BO_ 166 LKAS_COMMAND: 8 XXX
 SG_ LKAS_STEERING_TORQUE : 10|11@0+ (1,-1024) [0|1] "" XXX
 SG_ LKAS_CONTROL_BIT : 24|3@1+ (1,0) [0|1] "" XXX
 SG_ DASM_FAULT : 51|1@0+ (1,0) [0|1] "" XXX
 SG_ COUNTER : 55|4@0+ (1,0) [0|15] "" XXX
 SG_ CHECKSUM : 63|8@0+ (1,0) [0|255] "" XXX

BO_ 258 STEERING: 8 XXX
 SG_ STEER_ANGLE : 5|14@0+ (0.5,-2048) [-2048|2047] "deg" XXX
 SG_ STEERING_RATE : 21|14@0+ (0.5,-2048) [-2048|2047] "deg/s" XXX
 SG_ UNKNOWN_STEERING : 50|3@0+ (1,0) [0|15] "" XXX
 SG_ COUNTER : 55|4@0+ (1,0) [0|15] "" XXX
 SG_ CHECKSUM : 63|8@0+ (1,0) [0|255] "" XXX

BO_ 284 ESP_8: 8 XXX
 SG_ BRK_PRESSURE : 3|12@0+ (1,0) [0|1] "" XXX
 SG_ BRAKE_PEDAL : 19|12@0+ (1,0) [0|1] "" XXX
 SG_ Vehicle_Speed : 39|16@0+ (0.0078125,0) [0|511.984375] "km/h" XXX
 SG_ COUNTER : 55|4@0+ (1,0) [0|15] "" XXX
 SG_ CHECKSUM : 63|8@0+ (1,0) [0|255] "" XXX

BO_ 320 ESP_1: 8 XXX
 SG_ Brake_Pedal_State : 2|2@1+ (1,0) [0|0] "" XXX
 SG_ Vehicle_Speed : 33|10@0+ (0.5,0) [0|511] "km/h" XXX
 SG_ COUNTER : 55|4@0+ (1,0) [0|15] "" XXX
 SG_ CHECKSUM : 63|8@0+ (1,0) [0|255] "" XXX
 SG_ BRAKE_PRESSED_ACC : 6|1@0+ (1,0) [0|3] "" XXX

BO_ 344 ESP_6: 8 XXX
 SG_ WHEEL_SPEED_FL : 5|14@0+ (0.5,0) [0|8191] "rpm" XXX
 SG_ WHEEL_SPEED_FR : 21|14@0+ (0.5,0) [0|8191] "rpm" XXX
 SG_ WHEEL_SPEED_RL : 37|14@0+ (0.5,0) [0|8191] "rpm" XXX
 SG_ WHEEL_SPEED_RR : 53|14@0+ (0.5,0) [0|8191] "rpm" XXX

BO_ 464 ORC_1: 8 XXX
 SG_ SEATBELT_DRIVER_UNLATCHED : 13|1@0+ (1,0) [0|1] "" XXX

BO_ 500 DAS_3: 8 XXX
 SG_ ENGINE_TORQUE_REQUEST : 4|13@0+ (0.25,-500) [-500|1547.5] "Nm" XXX
 SG_ ENGINE_TORQUE_REQUEST_MAX : 7|1@0+ (1,0) [0|1] "" XXX
 SG_ ACC_STANDSTILL : 5|1@0+ (1,0) [0|1] ""  XXX
 SG_ ACC_AVAILABLE : 20|1@0+ (1,0) [0|1] "" XXX
 SG_ ACC_ACTIVE : 21|1@0+ (1,0) [0|1] "" XXX
 SG_ ACC_FAULTED : 47|1@0+ (1,0) [0|1] "" XXX
 SG_ BRAKE_MAYBE : 18|11@0+ (1,0) [0|255] "" XXX
 SG_ BRAKE_BOOL_1 : 36|1@0+ (1,0) [0|3] "" XXX
 SG_ COUNTER : 55|4@0+ (1,0) [0|15] "" XXX
 SG_ CHECKSUM : 63|8@0+ (1,0) [0|255] "" XXX

BO_ 544 EPS_2: 8 XXX
 SG_ LKAS_STATE : 23|4@0+ (1,0) [0|15] "" XXX
 SG_ COLUMN_TORQUE : 2|11@0+ (1,-1024) [-1024|1023] "" XXX
 SG_ TORQUE_OVERLAY_STATUS : 6|4@0+ (1,0) [0|15] "" XXX
 SG_ EPS_TORQUE_MOTOR_RAW : 19|12@0+ (1,-2048) [-2048|2047] "" XXX
 SG_ EPS_TORQUE_MOTOR : 34|11@0+ (1,-1024) [-1024|1023] "" XXX
 SG_ AUTO_PARK_HAS_CONTROL_2 : 51|1@0+ (1,0) [0|1] "" XXX
 SG_ COUNTER : 55|4@0+ (1,0) [0|15] "" XXX
 SG_ CHECKSUM : 63|8@0+ (1,0) [0|255] "" XXX

BO_ 559 ECM_5: 8 XXX
 SG_ Accelerator_Position : 0|8@1+ (0.4,0) [0|100] "%" XXX
 SG_ COUNTER : 55|4@0+ (1,0) [0|15] "" XXX
 SG_ CHECKSUM : 63|8@0+ (1,0) [0|255] "" XXX

BO_ 571 CRUISE_BUTTONS: 3 XXX
 SG_ ACC_Cancel : 0|1@1+ (1,0) [0|0] "" XXX
 SG_ ACC_Distance_Dec : 1|1@1+ (1,0) [0|0] "" XXX
 SG_ ACC_Accel : 2|1@1+ (1,0) [0|0] "" XXX
 SG_ ACC_Decel : 3|1@1+ (1,0) [0|0] "" XXX
 SG_ ACC_Resume : 4|1@0+ (1,0) [0|1] "" XXX
 SG_ Cruise_OnOff : 6|1@1+ (1,0) [0|0] "" XXX
 SG_ ACC_OnOff : 7|1@1+ (1,0) [0|0] "" XXX
 SG_ ACC_Distance_Inc : 8|1@1+ (1,0) [0|0] "" XXX
 SG_ COUNTER : 15|4@0+ (1,0) [0|15] "" XXX
 SG_ CHECKSUM : 23|8@0+ (1,0) [0|255] "" XXX

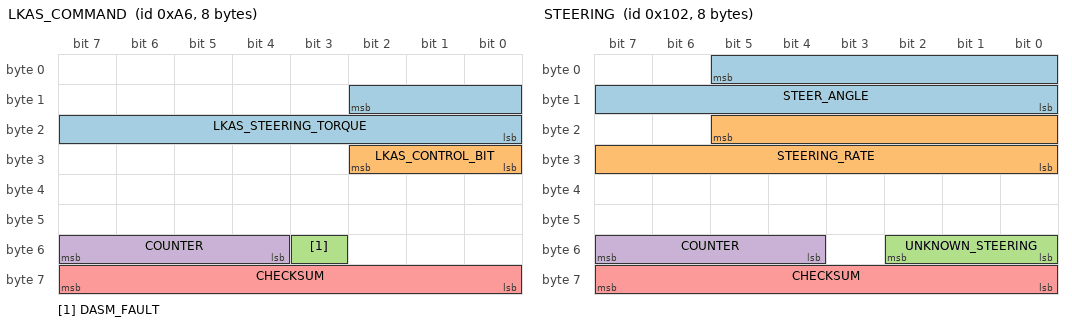
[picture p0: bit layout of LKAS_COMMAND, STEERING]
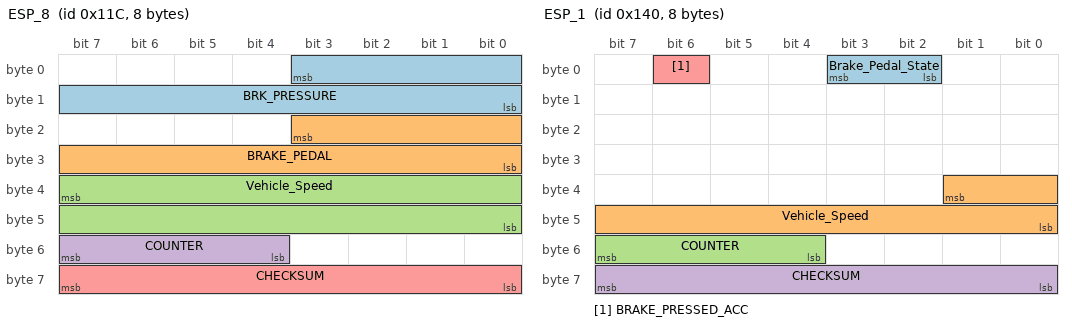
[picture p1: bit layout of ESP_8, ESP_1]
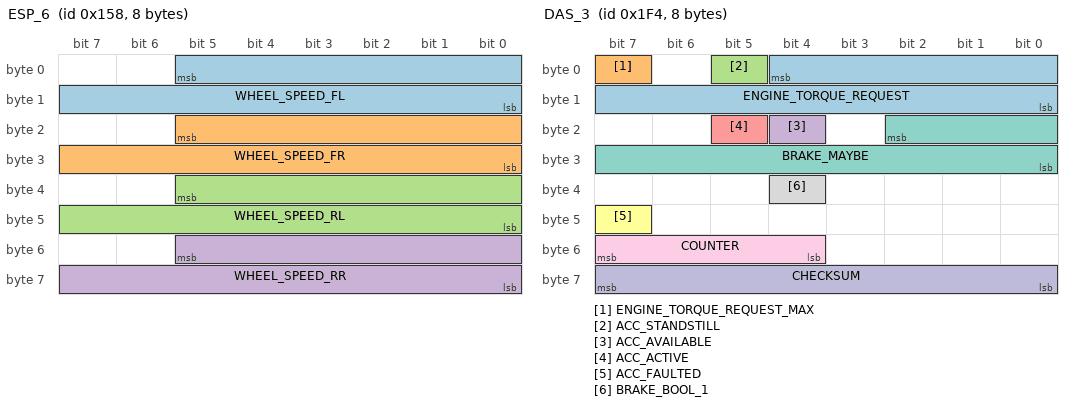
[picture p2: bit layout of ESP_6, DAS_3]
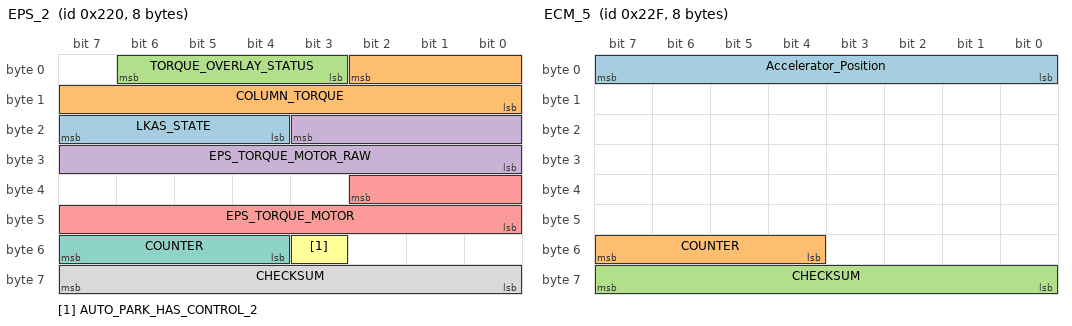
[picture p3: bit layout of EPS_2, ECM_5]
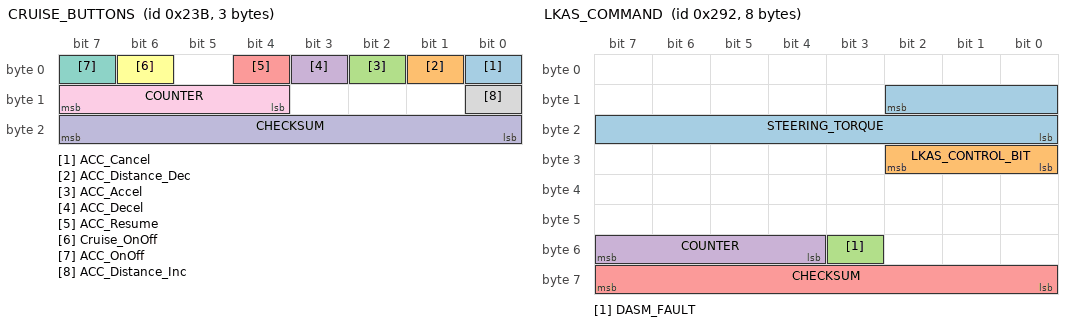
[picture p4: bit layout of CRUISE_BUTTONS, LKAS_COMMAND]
BO_ 658 LKAS_COMMAND: 8 XXX
 SG_ STEERING_TORQUE : 10|11@0+ (1,-1024) [0|1] "" XXX
 SG_ LKAS_CONTROL_BIT : 24|3@1+ (1,0) [0|1] "" XXX
 SG_ DASM_FAULT : 51|1@0+ (1,0) [0|1] "" XXX
 SG_ COUNTER : 55|4@0+ (1,0) [0|15] "" XXX
 SG_ CHECKSUM : 63|8@0+ (1,0) [0|255] "" XXX

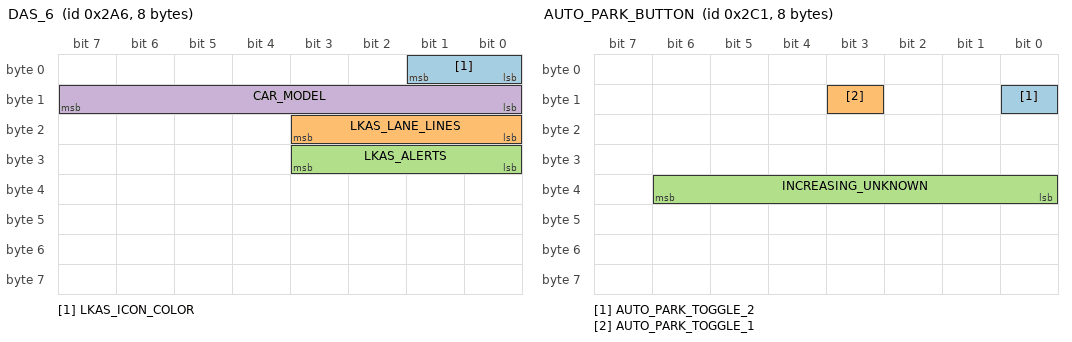
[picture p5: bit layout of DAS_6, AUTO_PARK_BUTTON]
BO_ 678 DAS_6: 8 XXX
 SG_ LKAS_ICON_COLOR : 1|2@0+ (1,0) [0|3] "" XXX
 SG_ LKAS_LANE_LINES : 19|4@0+ (1,0) [0|1] "" XXX
 SG_ LKAS_ALERTS : 27|4@0+ (1,0) [0|1] "" XXX
 SG_ CAR_MODEL : 15|8@0+ (1,0) [0|255] "" XXX

BO_ 705 AUTO_PARK_BUTTON: 8 XXX
 SG_ AUTO_PARK_TOGGLE_2 : 8|1@0+ (1,0) [0|1] "" XXX
 SG_ AUTO_PARK_TOGGLE_1 : 11|1@0+ (1,0) [0|1] "" XXX
 SG_ INCREASING_UNKNOWN : 38|7@0+ (1,0) [0|15] "" XXX

BO_ 720 BSM_1: 6 XXX
 SG_ RIGHT_STATUS : 0|3@1+ (1,0) [0|0] "" XXX
 SG_ LEFT_STATUS : 3|3@1+ (1,0) [0|0] "" XXX

BO_ 792 STEERING_LEVERS: 8 XXX
 SG_ TURN_SIGNALS : 0|2@1+ (1,0) [0|3] "" XXX
 SG_ HIGH_BEAM_PUSHED_IN : 2|1@0+ (1,0) [0|3] "" XXX

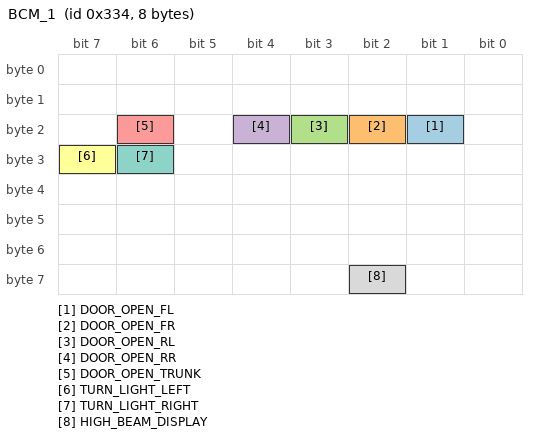
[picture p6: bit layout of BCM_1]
BO_ 820 BCM_1: 8 XXX
 SG_ DOOR_OPEN_FL : 17|1@0+ (1,0) [0|1] "" XXX
 SG_ DOOR_OPEN_FR : 18|1@0+ (1,0) [0|1] "" XXX
 SG_ DOOR_OPEN_RL : 19|1@0+ (1,0) [0|1] "" XXX
 SG_ DOOR_OPEN_RR : 20|1@0+ (1,0) [0|1] "" XXX
 SG_ DOOR_OPEN_TRUNK : 22|1@0+ (1,0) [0|1] "" XXX
 SG_ TURN_LIGHT_LEFT : 31|1@0+ (1,0) [0|1] "" XXX
 SG_ TURN_LIGHT_RIGHT : 30|1@0+ (1,0) [0|1] "" XXX
 SG_ HIGH_BEAM_DISPLAY : 58|1@0+ (1,0) [0|1] "" XXX

CM_ SG_ 658 LKAS_CONTROL_BIT "0=IDLE, 1=HAS 2=LKAS 3=ABSD, 4=TJA, 7=SNA";
CM_ SG_ 678 LKAS_ICON_COLOR "3 is yellow, 2 is green, 1 is white, 0 is null";
CM_ SG_ 678 LKAS_LANE_LINES "0x01 transparent lines, 0x02 left white, 0x03 right white, 0x04 left yellow with car on top, 0x05 left yellow with car on top, 0x06 both white, 0x07 left yellow, 0x08 left yellow right white, 0x09 right yellow, 0x0a right yellow left white, 0x0b left yellow with car on top right white, 0x0c right yellow with car on top left white, (0x00, 0x0d, 0x0e, 0x0f) null";
CM_ SG_ 678 LKAS_ALERTS "(0x01, 0x02) lane sense off, (0x03, 0x04, 0x06) place hands on steering wheel, 0x07 lane departure detected + place hands on steering wheel, (0x08, 0x09) lane sense unavailable + clean front windshield, 0x0b lane sense and auto high beam unavailable + clean front windshield, 0x0c lane sense unavailable + service required, (0x00, 0x05, 0x0a, 0x0d, 0x0e, 0x0f) null";
